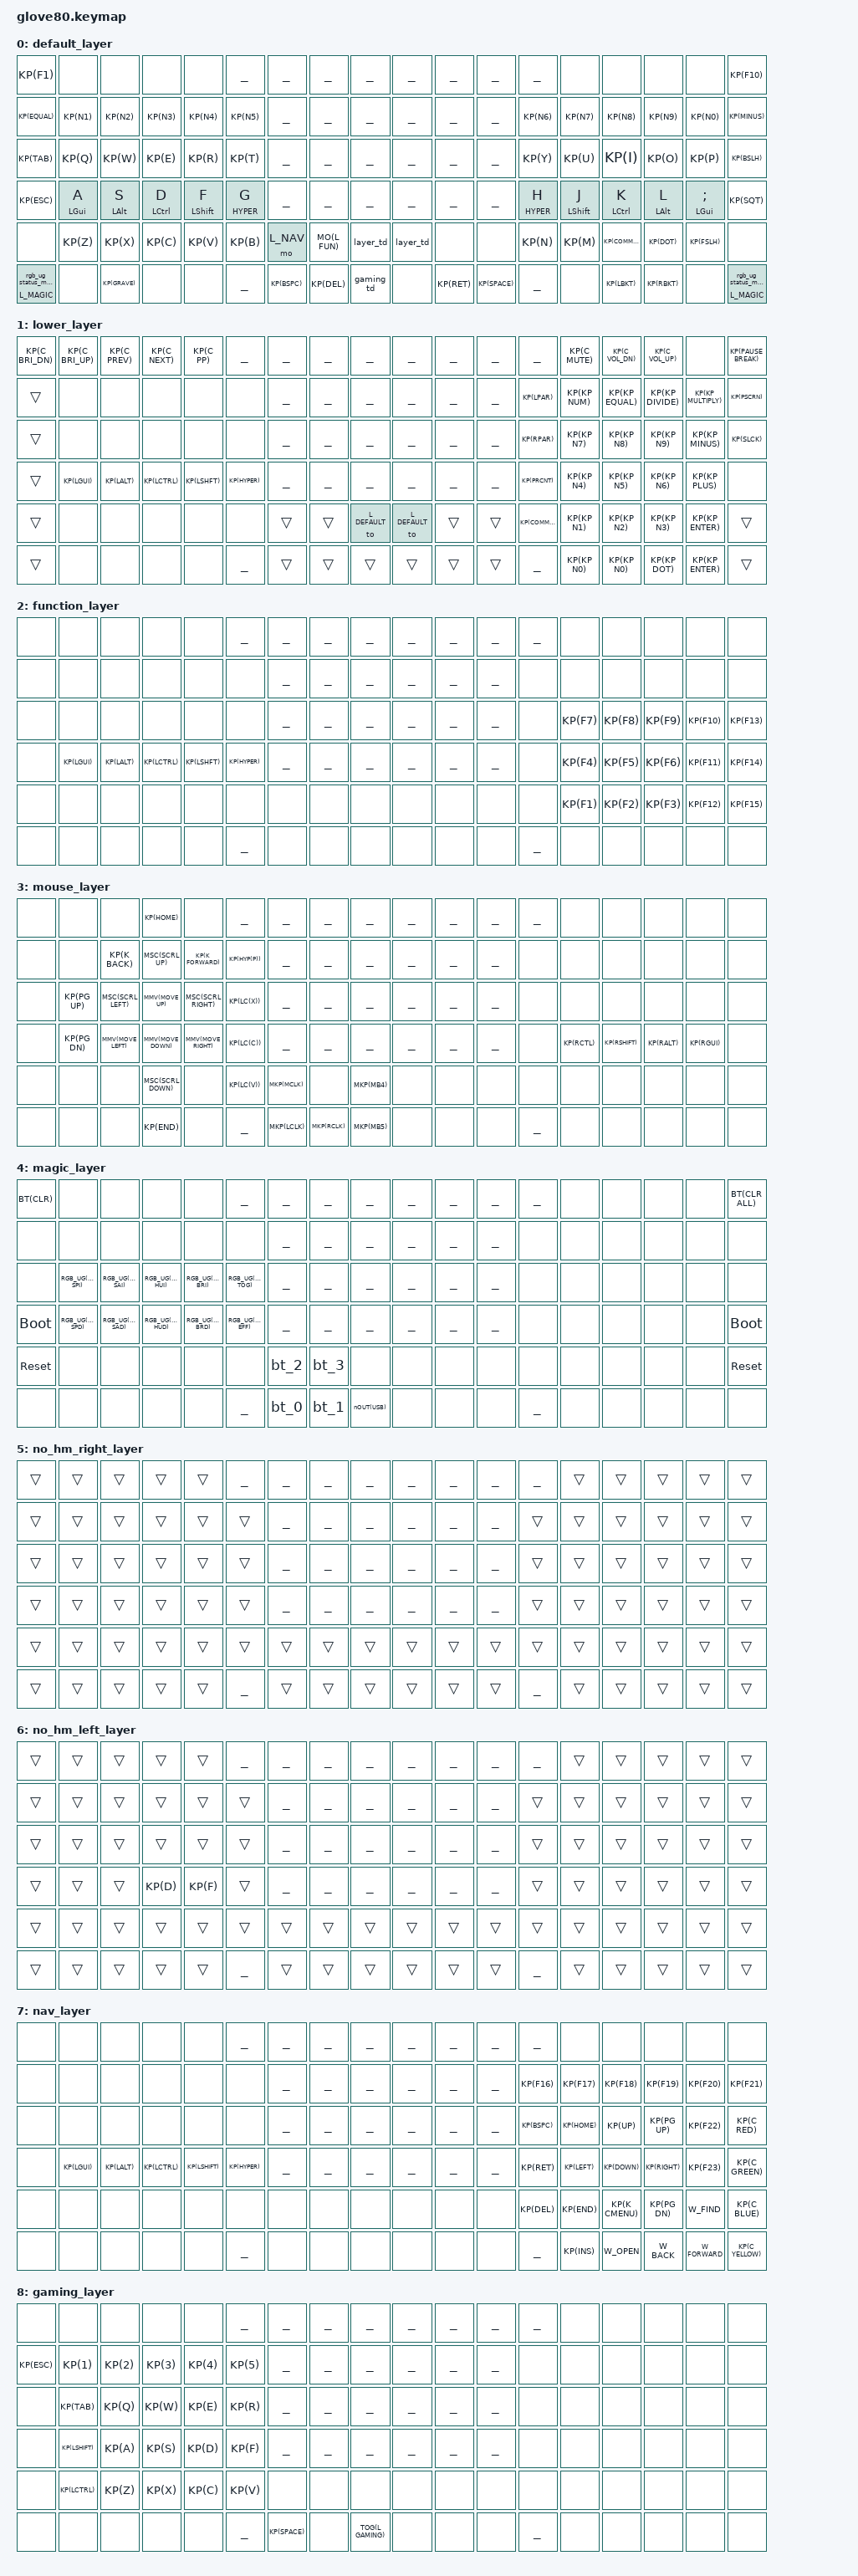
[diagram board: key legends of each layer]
/*
 * Copyright (c) 2020 The ZMK Contributors
 *
 * SPDX-License-Identifier: MIT
 */

#include <behaviors.dtsi>
#include <dt-bindings/zmk/keys.h>
#include <dt-bindings/zmk/bt.h>
#include <dt-bindings/zmk/ext_power.h>
#include <dt-bindings/zmk/outputs.h>
#include <dt-bindings/zmk/rgb.h>

#define ZMK_POINTING_DEFAULT_MOVE_VAL 600  // default: 600
#define ZMK_POINTING_DEFAULT_SCRL_VAL 20   // default: 10
#include <dt-bindings/zmk/pointing.h>

#define HYPER LC(LS(LG(LALT)))
#define HYP(x) LC(LS(LG(LA(x))))

// layers
#define L_DEFAULT     0
#define L_LOWER       1
#define L_FUN    2
#define L_MOUSE       3
#define L_MAGIC       4
#define L_NO_HM_RIGHT 5
#define L_NO_HM_LEFT  6
#define L_NAV         7
#define L_GAMING      8
#define TOG(LAYER) &tog LAYER

&lt {
    quick-tap-ms = <175>;
};

&caps_word {
    continue-list = <UNDERSCORE>;
};

/ {
    behaviors {
        // For the "layer" key, it'd nice to be able to use it as either a shift or a toggle.
        // Configure it as a tap dance, so the first tap (or hold) is a &mo and the second tap is a &to
        layer_td: tap_dance_0 {
            compatible = "zmk,behavior-tap-dance";
            label = "LAYER_TAP_DANCE";
            #binding-cells = <0>;
            tapping-term-ms = <200>;
            bindings = <&mo L_LOWER>, <&to L_LOWER>;
        };

        gaming_td: gaming_td {
            compatible = "zmk,behavior-tap-dance";
            label = "GAMING_CAPS_TAP_DANCE";
            #binding-cells = <0>;
            tapping-term-ms = <200>;
            bindings = <&caps_word>, <&tog L_GAMING>;
        };


        magic: magic_hold_tap {
            compatible = "zmk,behavior-hold-tap";
            label = "MAGIC_HOLD_TAP";
            #binding-cells = <2>;
            flavor = "tap-preferred";
            tapping-term-ms = <200>;
            bindings = <&mo>, <&rgb_ug_status_macro>;
        };

        hml: home_row_mod_left {
            compatible = "zmk,behavior-hold-tap";
            #binding-cells = <2>;
            flavor = "balanced";
            // require-prior-idle-ms = <150>;
            tapping-term-ms = <280>;
            quick-tap-ms = <175>;
            bindings = <&kp>, <&kp>;
            hold-trigger-key-positions = <5 6 7 8 9 16 17 18 19 20 21 28 29 30 31 32 33 40 41 42 43 44 45 55 56 57 58 59 60 61 62 63 72 73 74 75 76 77 78 79>; // List of keys on the right side of the keyboard
            hold-trigger-on-release;
        };
        hmr: home_row_mod_right {
            compatible = "zmk,behavior-hold-tap";
            #binding-cells = <2>;
            flavor = "balanced";
            // require-prior-idle-ms = <150>;
            tapping-term-ms = <280>;
            quick-tap-ms = <175>;
            bindings = <&kp_no_hm_left>, <&kp>;
            hold-trigger-key-positions = <0 1 2 3 4 10 11 12 13 14 15 22 23 24 25 26 27 34 35 36 37 38 39 46 47 48 49 50 51 52 53 54 64 65 66 67 68 69 70 71>; // List of keys on the left side of the keyboard
            hold-trigger-on-release;
        };

        slash_undo: slash_undo {
            compatible = "zmk,behavior-mod-morph";
            #binding-cells = <0>;
            bindings = <&kp FSLH>, <&kp K_UNDO>;
            mods = <(MOD_RCTL|MOD_LCTL)>;
        };
    };

    macros {
        kp_no_hm_left: kp_no_hm_left {
            compatible = "zmk,behavior-macro-one-param";
            wait-ms = <0>;
            tap-ms = <0>;
            #binding-cells = <1>;
            bindings
                = <&macro_press &mo L_NO_HM_LEFT>
                , <&macro_param_1to1>
                , <&macro_press &kp MACRO_PLACEHOLDER>
                , <&macro_pause_for_release>
                , <&macro_param_1to1>
                , <&macro_release &kp MACRO_PLACEHOLDER>
                , <&macro_release &mo L_NO_HM_LEFT>
                ;
        };

        rgb_ug_status_macro: rgb_ug_status_macro_0 {
            label = "RGB_UG_STATUS";
            compatible = "zmk,behavior-macro";
            #binding-cells = <0>;
            bindings
                = <&rgb_ug RGB_STATUS>;
        };

        bt_0: bt_profile_macro_0 {
            label = "BT_0";
            compatible = "zmk,behavior-macro";
            #binding-cells = <0>;
            bindings
                = <&out OUT_BLE>,
                  <&bt BT_SEL 0>;
        };

        bt_1: bt_profile_macro_1 {
            label = "BT_1";
            compatible = "zmk,behavior-macro";
            #binding-cells = <0>;
            bindings
                = <&out OUT_BLE>,
                  <&bt BT_SEL 1>;
        };

        bt_2: bt_profile_macro_2 {
            label = "BT_2";
            compatible = "zmk,behavior-macro";
            #binding-cells = <0>;
            bindings
                = <&out OUT_BLE>,
                  <&bt BT_SEL 2>;
        };

        bt_3: bt_profile_macro_3 {
            label = "BT_3";
            compatible = "zmk,behavior-macro";
            #binding-cells = <0>;
            bindings
                = <&out OUT_BLE>,
                  <&bt BT_SEL 3>;
        };
    };

    // no-op to make it easy to align bindings on space
    #define _____

    #define HM_A &hml LGUI A
    #define HM_S &hml LALT S
    #define HM_D &hml LCTRL D
    #define HM_F &hml LSHFT F
    #define HM_G &hml HYPER G

    #define HM_H &hmr HYPER H
    #define HM_J &hmr LSHFT J
    #define HM_K &hmr LCTRL K
    #define HM_L &hmr LALT L
    #define HM_SEMI &hmr LGUI SEMI

    #define T_RET &lt L_MOUSE RET
    #define T_ESC &lt L_FUN ESC

    #define T_LCTL &mo L_NAV
    #define MO(x) &mo x

    #define BT(x) &bt BT_##x
    #define KP(x) &kp x
    #define MAGIC &magic L_MAGIC 0
    #define MKP(x) &mkp x
    #define MMV(x) &mmv x
    #define MSC(x) &msc x
    #define RGB_UG(x) &rgb_ug x
    #define TO_DEF &to L_DEFAULT
    #define nOUT(x) &out OUT_##x

    #define POS_L11 0
    #define POS_L12 1
    #define POS_L13 2
    #define POS_L14 3
    #define POS_L15 4
    #define POS_R11 5
    #define POS_R12 6
    #define POS_R13 7
    #define POS_R14 8
    #define POS_R15 9
    #define POS_L21 10
    #define POS_L22 11
    #define POS_L23 12
    #define POS_L24 13
    #define POS_L25 14
    #define POS_L26 15
    #define POS_R21 16
    #define POS_R22 17
    #define POS_R23 18
    #define POS_R24 19
    #define POS_R25 20
    #define POS_R26 21
    #define POS_L31 22
    #define POS_L32 23
    #define POS_L33 24
    #define POS_L34 25
    #define POS_L35 26
    #define POS_L36 27
    #define POS_R31 28
    #define POS_R32 29
    #define POS_R33 30
    #define POS_R34 31
    #define POS_R35 32
    #define POS_R36 33
    #define POS_L41 34
    #define POS_L42 35
    #define POS_L43 36
    #define POS_L44 37
    #define POS_L45 38
    #define POS_L46 39
    #define POS_R41 40
    #define POS_R42 41
    #define POS_R43 42
    #define POS_R44 43
    #define POS_R45 44
    #define POS_R46 45
    #define POS_L51 46
    #define POS_L52 47
    #define POS_L53 48
    #define POS_L54 49
    #define POS_L55 50
    #define POS_L56 51
    #define POS_TL11 52
    #define POS_TL12 53
    #define POS_TL13 54
    #define POS_TR11 55
    #define POS_TR12 56
    #define POS_TR13 57
    #define POS_R51 58
    #define POS_R52 59
    #define POS_R53 60
    #define POS_R54 61
    #define POS_R55 62
    #define POS_R56 63
    #define POS_L61 64
    #define POS_L62 65
    #define POS_L63 66
    #define POS_L64 67
    #define POS_L65 68
    #define POS_TL21 69
    #define POS_TL22 70
    #define POS_TL23 71
    #define POS_TR21 72
    #define POS_TR22 73
    #define POS_TR23 74
    #define POS_R61 75
    #define POS_R62 76
    #define POS_R63 77
    #define POS_R64 78
    #define POS_R65 79

    /* combos {
        compatible = "zmk,combos";

        combo_function_layer {
            timeout-ms = <50>;
            key-positions = <POS_TL13 POS_TL23>;
            bindings = <&mo L_FUN>;
        };

        combo_mouse_layer {
            timeout-ms = <50>;
            key-positions = <POS_TR11 POS_TR12>;
            bindings = <&mo L_MOUSE>;
        };
    };*/

    keymap {
        compatible = "zmk,keymap";

        /*
        _layer {
            bindings = <
            &none &none &none &none &none _____ _____ _____ _____ _____ _____ _____ _____ &none &none &none &none &none
            &none &none &none &none &none &none _____ _____ _____ _____ _____ _____ &none &none &none &none &none &none
            &none &none &none &none &none &none _____ _____ _____ _____ _____ _____ &none &none &none &none &none &none
            &none &none &none &none &none &none _____ _____ _____ _____ _____ _____ &none &none &none &none &none &none
            &none &none &none &none &none &none &none &none &none &none &none &none &none &none &none &none &none &none
            &none &none &none &none &none _____ &none &none &none &none &none &none _____ &none &none &none &none &none
            >;
        };
        _layer {
            bindings = <
            &trans &trans &trans &trans &trans _____  _____  _____  _____  _____  _____  _____  _____  &trans &trans &trans &trans &trans
            &trans &trans &trans &trans &trans &trans _____  _____  _____  _____  _____  _____  &trans &trans &trans &trans &trans &trans
            &trans &trans &trans &trans &trans &trans _____  _____  _____  _____  _____  _____  &trans &trans &trans &trans &trans &trans
            &trans &trans &trans &trans &trans &trans _____  _____  _____  _____  _____  _____  &trans &trans &trans &trans &trans &trans
            &trans &trans &trans &trans &trans &trans &trans &trans &trans &trans &trans &trans &trans &trans &trans &trans &trans &trans
            &trans &trans &trans &trans &trans _____  &trans &trans &trans &trans &trans &trans _____  &trans &trans &trans &trans &trans
            >;
        };
        */

        default_layer {
            // ---------------------------------------------------------------------------------------------------------------------------------
            // |  F1   |  F2 |  F3 |  F4  |  F5  |                                                               |  F6   |  F7   |  F8  |   F9  |  F10 |  10 (0-9): l:0-4 r:5-9
            // |  =    |  1  |  2  |  3   |  4   |  5   |                                                 |  6   |   7   |   8   |  9   |   0   |   -  |  12 (10-21) l:10-15 r:16-21
            // |  TAB  |  Q  |  W  |  E   |  R   |  T   |                                                 |  Y   |   U   |   I   |  O   |   P   |   \  |  12 (22-33) l:22-27 r:28-33
            // |  ESC  |  A  |  S  |  D   |  F   |  G   |                                                 |  H   |   J   |   K   |  L   |   ;   |   '  |  12 (34-45) l:34-39 r:40-45
            // |   `   |  Z  |  X  |  C   |  V   |  B   | LSHFT | LCTRL | LOWER | | LGUI  | RCTRL | RSHFT |  N   |   M   |   ,   |  .   |   /   | PGUP |  6+3+3+6 (46-63) l:46-54 r:55-63
            // | MAGIC | HOME| END | LEFT | RIGHT|      | BSPC  | DEL   | LALT  | | RALT  | RET   | SPACE |      |  UP   | DOWN  |  [   |   ]   | PGDN |  5+3+3+5 (64-79) l:64-71 r:72-79

            bindings = <
            KP(F1)    &none  &none     &none  &none  _____  _____    _____     _____      _____     _____   _____     _____  &none  &none     &none    &none    KP(F10)
            KP(EQUAL) KP(N1) KP(N2)    KP(N3) KP(N4) KP(N5) _____    _____     _____      _____     _____   _____     KP(N6) KP(N7) KP(N8)    KP(N9)   KP(N0)   KP(MINUS)
            KP(TAB)   KP(Q)  KP(W)     KP(E)  KP(R)  KP(T)  _____    _____     _____      _____     _____   _____     KP(Y)  KP(U)  KP(I)     KP(O)    KP(P)    KP(BSLH)
            KP(ESC)   HM_A   HM_S      HM_D   HM_F   HM_G   _____    _____     _____      _____     _____   _____     HM_H   HM_J   HM_K      HM_L     HM_SEMI  KP(SQT)
            &none     KP(Z)  KP(X)     KP(C)  KP(V)  KP(B)  T_LCTL   MO(L_FUN) &layer_td  &layer_td &none   &none     KP(N)  KP(M)  KP(COMMA) KP(DOT)  KP(FSLH) &none
            MAGIC     &none  KP(GRAVE) &none  &none  _____  KP(BSPC) KP(DEL)   &gaming_td &none     KP(RET) KP(SPACE) _____  &none  KP(LBKT)  KP(RBKT) &none    MAGIC
            >;
        };

        lower_layer {
            bindings = <
            KP(C_BRI_DN) KP(C_BRI_UP) KP(C_PREV) KP(C_NEXT) KP(C_PP)  _____     _____  _____  _____  _____  _____  _____  _____     KP(C_MUTE) KP(C_VOL_DN) KP(C_VOL_UP)  &none           KP(PAUSE_BREAK)
            &trans       &none        &none      &none      &none     &none     _____  _____  _____  _____  _____  _____  KP(LPAR)  KP(KP_NUM) KP(KP_EQUAL) KP(KP_DIVIDE) KP(KP_MULTIPLY) KP(PSCRN)
            &trans       &none        &none      &none      &none     &none     _____  _____  _____  _____  _____  _____  KP(RPAR)  KP(KP_N7)  KP(KP_N8)    KP(KP_N9)     KP(KP_MINUS)    KP(SLCK)
            &trans       KP(LGUI)     KP(LALT)   KP(LCTRL)  KP(LSHFT) KP(HYPER) _____  _____  _____  _____  _____  _____  KP(PRCNT) KP(KP_N4)  KP(KP_N5)    KP(KP_N6)     KP(KP_PLUS)     &none
            &trans       &none        &none      &none      &none     &none     &trans &trans TO_DEF TO_DEF &trans &trans KP(COMMA) KP(KP_N1)  KP(KP_N2)    KP(KP_N3)     KP(KP_ENTER)    &trans
            &trans       &none        &none      &none      &none     _____     &trans &trans &trans &trans &trans &trans _____     KP(KP_N0)  KP(KP_N0)    KP(KP_DOT)    KP(KP_ENTER)    &trans
            >;
        };

        function_layer {
            bindings = <
            &none &none    &none    &none     &none     _____     _____ _____ _____ _____ _____ _____ _____ &none  &none  &none  &none   &none
            &none &none    &none    &none     &none     &none     _____ _____ _____ _____ _____ _____ &none &none  &none  &none  &none   &none
            &none &none    &none    &none     &none     &none     _____ _____ _____ _____ _____ _____ &none KP(F7) KP(F8) KP(F9) KP(F10) KP(F13)
            &none KP(LGUI) KP(LALT) KP(LCTRL) KP(LSHFT) KP(HYPER) _____ _____ _____ _____ _____ _____ &none KP(F4) KP(F5) KP(F6) KP(F11) KP(F14)
            &none &none    &none    &none     &none     &none     &none &none &none &none &none &none &none KP(F1) KP(F2) KP(F3) KP(F12) KP(F15)
            &none &none    &none    &none     &none     _____     &none &none &none &none &none &none _____ &none  &none  &none  &none   &none
            >;
        };

        mouse_layer {
            bindings = <
            &none &none     &none          KP(HOME)       &none           _____      _____     _____     _____    _____ _____ _____ _____ &none    &none      &none    &none    &none
            &none &none     KP(K_BACK)     MSC(SCRL_UP)   KP(K_FORWARD)   KP(HYP(P)) _____     _____     _____    _____ _____ _____ &none &none    &none      &none    &none    &none
            &none KP(PG_UP) MSC(SCRL_LEFT) MMV(MOVE_UP)   MSC(SCRL_RIGHT) KP(LC(X))  _____     _____     _____    _____ _____ _____ &none &none    &none      &none    &none    &none
            &none KP(PG_DN) MMV(MOVE_LEFT) MMV(MOVE_DOWN) MMV(MOVE_RIGHT) KP(LC(C))  _____     _____     _____    _____ _____ _____ &none KP(RCTL) KP(RSHIFT) KP(RALT) KP(RGUI) &none
            &none &none     &none          MSC(SCRL_DOWN) &none           KP(LC(V))  MKP(MCLK) &none     MKP(MB4) &none &none &none &none &none    &none      &none    &none    &none
            &none &none     &none          KP(END)        &none           _____      MKP(LCLK) MKP(RCLK) MKP(MB5) &none &none &none _____ &none    &none      &none    &none    &none
            >;
        };

        magic_layer {
            bindings = <
            BT(CLR)     &none           &none           &none           &none           _____           _____ _____ _____     _____ _____ _____ _____ &none &none &none &none BT(CLR_ALL)
            &none       &none           &none           &none           &none           &none           _____ _____ _____     _____ _____ _____ &none &none &none &none &none &none
            &none       RGB_UG(RGB_SPI) RGB_UG(RGB_SAI) RGB_UG(RGB_HUI) RGB_UG(RGB_BRI) RGB_UG(RGB_TOG) _____ _____ _____     _____ _____ _____ &none &none &none &none &none &none
            &bootloader RGB_UG(RGB_SPD) RGB_UG(RGB_SAD) RGB_UG(RGB_HUD) RGB_UG(RGB_BRD) RGB_UG(RGB_EFF) _____ _____ _____     _____ _____ _____ &none &none &none &none &none &bootloader
            &sys_reset  &none           &none           &none           &none           &none           &bt_2 &bt_3 &none     &none &none &none &none &none &none &none &none &sys_reset
            &none       &none           &none           &none           &none           _____           &bt_0 &bt_1 nOUT(USB) &none &none &none _____ &none &none &none &none &none
            >;
        };

        no_hm_right_layer {
            bindings = <
            &trans &trans &trans &trans &trans _____  _____  _____  _____  _____  _____  _____  _____  &trans &trans &trans &trans &trans
            &trans &trans &trans &trans &trans &trans _____  _____  _____  _____  _____  _____  &trans &trans &trans &trans &trans &trans
            &trans &trans &trans &trans &trans &trans _____  _____  _____  _____  _____  _____  &trans &trans &trans &trans &trans &trans
            &trans &trans &trans &trans &trans &trans _____  _____  _____  _____  _____  _____  &trans &trans &trans &trans &trans &trans
            &trans &trans &trans &trans &trans &trans &trans &trans &trans &trans &trans &trans &trans &trans &trans &trans &trans &trans
            &trans &trans &trans &trans &trans _____  &trans &trans &trans &trans &trans &trans _____  &trans &trans &trans &trans &trans
            >;
        };

        no_hm_left_layer {
            bindings = <
            &trans &trans &trans &trans &trans _____  _____  _____  _____  _____  _____  _____  _____  &trans &trans &trans &trans &trans
            &trans &trans &trans &trans &trans &trans _____  _____  _____  _____  _____  _____  &trans &trans &trans &trans &trans &trans
            &trans &trans &trans &trans &trans &trans _____  _____  _____  _____  _____  _____  &trans &trans &trans &trans &trans &trans
            &trans &trans &trans KP(D)  KP(F)  &trans _____  _____  _____  _____  _____  _____  &trans &trans &trans &trans &trans &trans
            &trans &trans &trans &trans &trans &trans &trans &trans &trans &trans &trans &trans &trans &trans &trans &trans &trans &trans
            &trans &trans &trans &trans &trans _____  &trans &trans &trans &trans &trans &trans _____  &trans &trans &trans &trans &trans
            >;
        };

        // fkeys:basic_13-24
        #define W_LAUNCH6     KP(F15)
        #define W_LAUNCH7     KP(F16)
        #define W_LAUNCH8     KP(F17)
        #define W_LAUNCH9     KP(F18)

        #define W_OPEN        KP(K_EXECUTE)
        #define W_FIND        KP(K_FIND)
        #define W_MENUKB      KP(C_MENU)
        #define W_CANCEL      KP(K_STOP)
        #define W_RELOAD      KP(K_REFRESH)

        #define W_BACK        KP(K_BACK)
        #define W_CALCULATOR  KP(K_CALCULATOR)
        #define W_FORWARD     KP(K_FORWARD)

        nav_layer {
            bindings = <
            &none &none    &none    &none     &none      _____     _____ _____ _____ _____ _____ _____ _____    &none    &none       &none     &none     &none
            &none &none    &none    &none     &none      &none     _____ _____ _____ _____ _____ _____ KP(F16)  KP(F17)  KP(F18)     KP(F19)   KP(F20)   KP(F21)
            &none &none    &none    &none     &none      &none     _____ _____ _____ _____ _____ _____ KP(BSPC) KP(HOME) KP(UP)      KP(PG_UP) KP(F22)   KP(C_RED)
            &none KP(LGUI) KP(LALT) KP(LCTRL) KP(LSHIFT) KP(HYPER) _____ _____ _____ _____ _____ _____ KP(RET)  KP(LEFT) KP(DOWN)    KP(RIGHT) KP(F23)   KP(C_GREEN)
            &none &none    &none    &none     &none      &none     &none &none &none &none &none &none KP(DEL)  KP(END)  KP(K_CMENU) KP(PG_DN) W_FIND    KP(C_BLUE)
            &none &none    &none    &none     &none      _____     &none &none &none &none &none &none _____    KP(INS)  W_OPEN      W_BACK    W_FORWARD KP(C_YELLOW)
            >;
        };

        gaming_layer {
            bindings = <
            &none   &none      &none &none &none _____ _____     _____ _____         _____ _____ _____ _____ &none &none &none &none &none
            KP(ESC) KP(1)      KP(2) KP(3) KP(4) KP(5) _____     _____ _____         _____ _____ _____ &none &none &none &none &none &none
            &none   KP(TAB)    KP(Q) KP(W) KP(E) KP(R) _____     _____ _____         _____ _____ _____ &none &none &none &none &none &none
            &none   KP(LSHIFT) KP(A) KP(S) KP(D) KP(F) _____     _____ _____         _____ _____ _____ &none &none &none &none &none &none
            &none   KP(LCTRL)  KP(Z) KP(X) KP(C) KP(V) &none     &none &none         &none &none &none &none &none &none &none &none &none
            &none   &none      &none &none &none _____ KP(SPACE) &none TOG(L_GAMING) &none &none &none _____ &none &none &none &none &none
            >;
        };
    };
};
